# R7FA6E10F register map
Vendor: Renesas Electronics Corporation; Series: RA6; File version: 1.10.02
CPU: CM33 r0p4, little endian, MPU, FPU, VTOR, 4 interrupt priority bits, 96 interrupts
Registers are 8-bit, read-write, reset 0x0 unless marked. A register's access mark holds for its fields unless they carry their own. Offsets are from the block's base; [hi:lo] are bit positions; 'fields as' and 'values as' point back to an identical list.

## DTC — Data Transfer Controller
Base 0x40005400
0x00 DTCCR reset 0x8 — DTC Control Register
  [4] RRS — DTC Transfer Information Read Skip Enable
    0=Transfer information read is not skipped; 1=Transfer information read is skipped when vector numbers match
0x04 DTCVBR 32-bit — DTC Vector Base Register
0x0C DTCST — DTC Module Start Register
  [0] DTCST — DTC Module Start
    0=DTC module stopped; 1=DTC module started
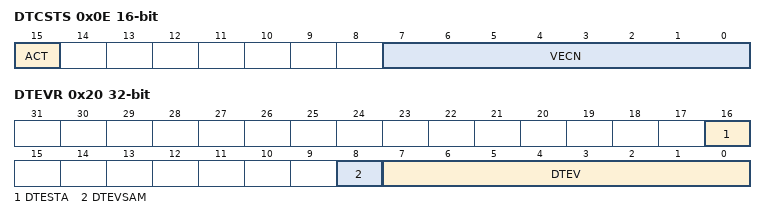
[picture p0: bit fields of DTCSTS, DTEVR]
0x0E DTCSTS 16-bit ro — DTC Status Register
  [15] ACT — DTC Active Flag
    0=DTC transfer operation is not in progress; 1=DTC transfer operation is in progress
  [7:0] VECN — DTC-Activating Vector Number Monitoring
0x10 DTCCR_SEC reset 0x8 — DTC Control Register for secure Region
  [4] RRS — DTC Transfer Information Read Skip Enable for Secure
    values as DTCCR.RRS
0x14 DTCVBR_SEC 32-bit — DTC Vector Base Register for secure Region
0x20 DTEVR 32-bit — DTC Error Vector Register
  [16] DTESTA — DTC Error Status Flag
    0=No DTC transfer error occurred; 1=DTC transfer error occurred
  [8] DTEVSAM ro — DTC Error Vector Number SA Monitor
    0=Secure vector number; 1=Non-Secure vector number
  [7:0] DTEV ro — DTC Error Vector Number

## CACHE
Base 0x40007000
0x00 CCACTL 32-bit — C-Cache Control Register
  [0] ENC — C-Cache Enable
    0=Disable C-cache; 1=Enable C-cache
0x04 CCAFCT 32-bit — C-Cache Flush Control Register
  [0] FC — C-Cache Flush
    0=No action; 1=C-cache line flush (all lines invalidated)
0x08 CCALCF 32-bit reset 0x1 — C-Cache Line Configuration Register
  [1:0] CC — C-Cache Line Size
    0=Prohibited; 1=Cache line size 32 bytes; 2=Cache line size 64 bytes; 3=Prohibited
0x40 SCACTL 32-bit — S-Cache Control Register
  [0] ENS — S-Cache Enable
    0=Disable S-cache; 1=Enable S-cache
0x44 SCAFCT 32-bit — S-Cache Flush Control Register
  [0] FS — S-Cache Flush
    0=No action; 1=S-cache line flush (all lines invalidated)
0x48 SCALCF 32-bit reset 0x1 — S-Cache Line Configuration Register
  [1:0] CS — S-Cache Line Size
    values as CCALCF.CC
0x200 CAPOAD 32-bit — Cache Parity Error Operation After Detection Register
  [0] OAD — Operation after Detection
    0=Non-maskable interrupt; 1=Reset
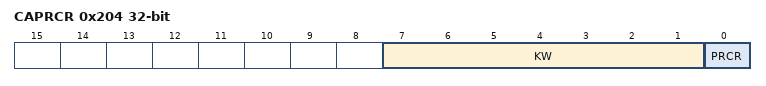
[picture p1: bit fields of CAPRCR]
0x204 CAPRCR 32-bit — Cache Protection Register
  [7:1] KW — Write key code
  [0] PRCR — Register Write Control
    0=Disable writes to protected registers; 1=Enable writes to protected registers

## DBG — Debug Function
Base 0x4001B000
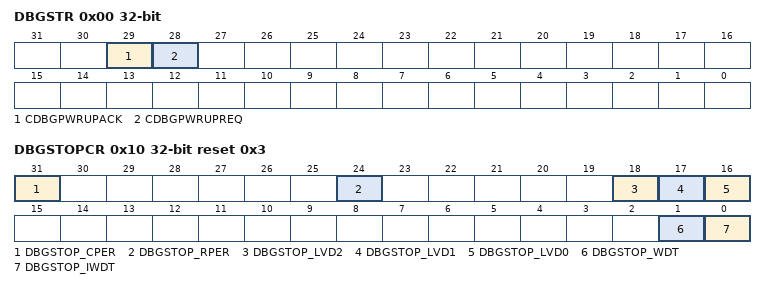
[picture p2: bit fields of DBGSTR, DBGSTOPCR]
0x00 DBGSTR 32-bit ro — Debug Status Register
  [29] CDBGPWRUPACK — Debug power-up acknowledge
    0=Debug power-up request is not acknowledged; 1=Debug power-up request is acknowledged
  [28] CDBGPWRUPREQ — Debug power-up request
    0=OCD is not requesting debug power up; 1=OCD is requesting debug power up
0x10 DBGSTOPCR 32-bit reset 0x3 — Debug Stop Control Register
  [31] DBGSTOP_CPER — Mask bit for Cache SRAM parity error reset/interrupt
    0=Enable Cache SRAM parity error reset/interrupt; 1=Mask Cache SRAM parity error reset/interrupt
  [24] DBGSTOP_RPER — Mask bit for SRAM parity error reset/interrupt
    0=Enable SRAM parity error reset/interrupt; 1=Mask SRAM parity error reset/interrupt
  [18] DBGSTOP_LVD2 — Mask bit for LVD2 reset/interrupt
    0=Enable LVD2 reset/interrupt; 1=Mask LVD2 reset/interrupt
  [17] DBGSTOP_LVD1 — Mask bit for LVD1 reset/interrupt
    0=Enable LVD1 reset/interrupt; 1=Mask LVD1 reset/interrupt
  [16] DBGSTOP_LVD0 — Mask bit for LVD0 reset
    0=Enable LVD0 reset; 1=Mask LVD0 reset
  [1] DBGSTOP_WDT — Mask bit for WDT reset/interrupt in the OCD run mode
    0=Enable WDT reset/interrupt; 1=Mask WDT reset/interrupt and stop WDT counter
  [0] DBGSTOP_IWDT — Mask bit for IWDT reset/interrupt in the OCD run mode
    0=Enable IWDT reset/interrupt; 1=Mask IWDT reset/interrupt and stop IWDT counter

## Notices in the file
This software is supplied by Renesas Electronics Corporation and is only intended for
use with Renesas products. No other uses are authorized. This software is owned by
Renesas Electronics Corporation and is protected under all applicable laws, including
copyright laws.
THIS SOFTWARE IS PROVIDED "AS IS" AND RENESAS MAKES NO WARRANTIES REGARDING
THIS SOFTWARE, WHETHER EXPRESS, IMPLIED OR STATUTORY, INCLUDING BUT NOT LIMITED TO
WARRANTIES OF MERCHANTABILITY, FITNESS FOR A PARTICULAR PURPOSE AND NON-INFRINGEMENT.
ALL SUCH WARRANTIES ARE EXPRESSLY DISCLAIMED. TO THE MAXIMUM EXTENT PERMITTED NOT
PROHIBITED BY LAW, NEITHER RENESAS ELECTRONICS CORPORATION NOR ANY OF ITS AFFILIATED
COMPANIES SHALL BE LIABLE FOR ANY DIRECT, INDIRECT, SPECIAL, INCIDENTAL OR CONSEQUENTIAL
DAMAGES FOR ANY REASON RELATED TO THIS SOFTWARE, EVEN IF RENESAS OR ITS AFFILIATES HAVE
BEEN ADVISED OF THE POSSIBILITY OF SUCH DAMAGES.
Renesas reserves the right, without notice, to make changes to this software and to
discontinue the availability of this software. By using this software, you agree to
the additional terms and conditions found by accessing the following link:
http://www.renesas.com/disclaimer
